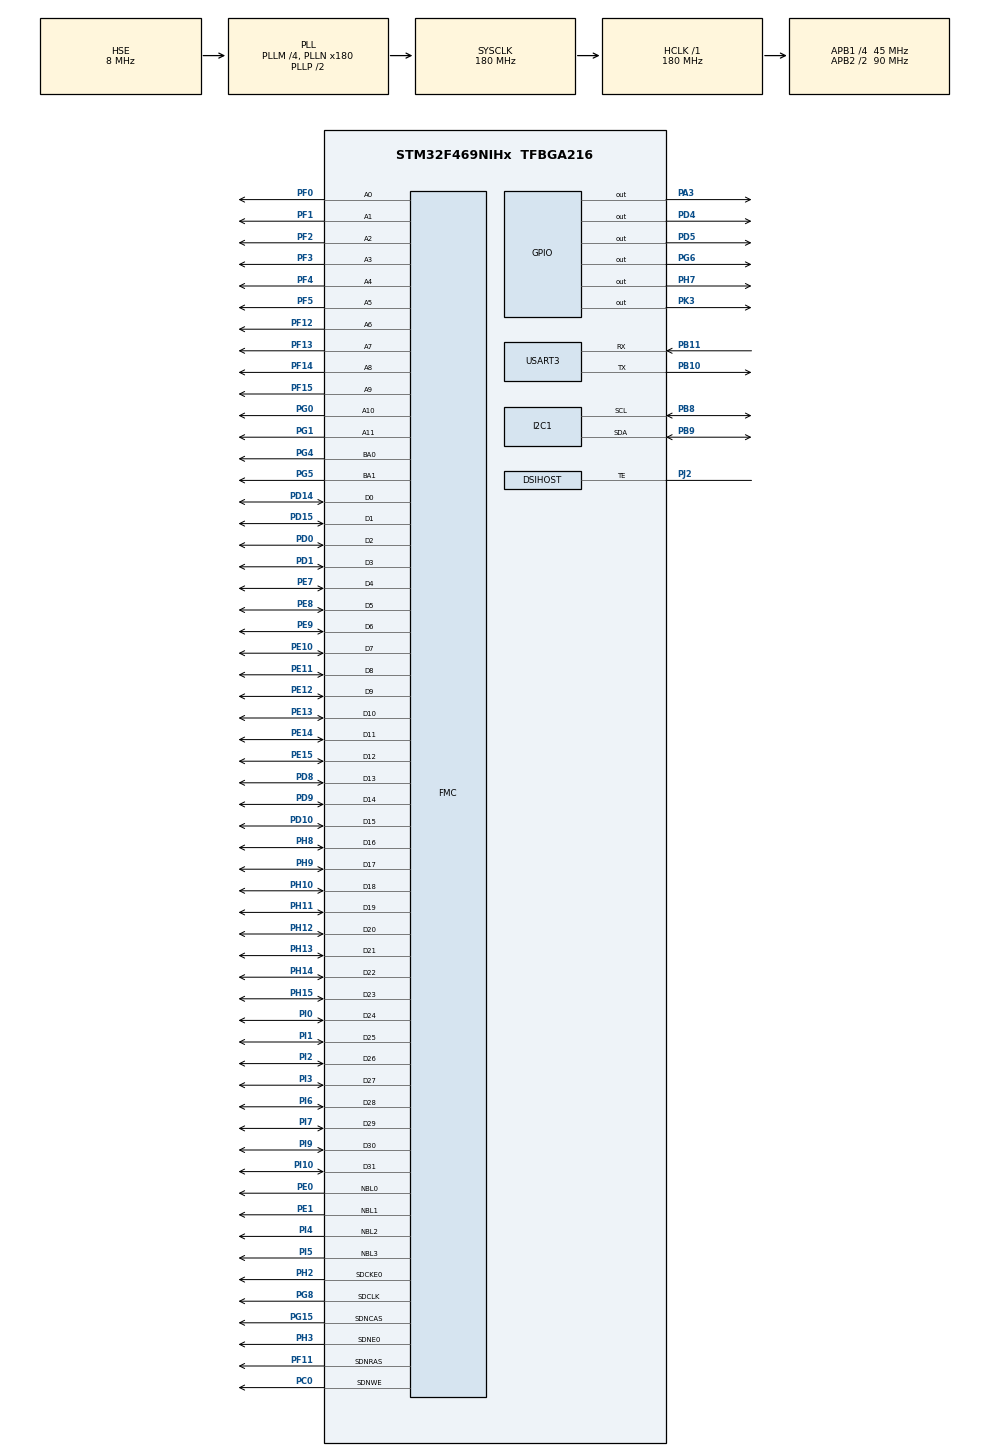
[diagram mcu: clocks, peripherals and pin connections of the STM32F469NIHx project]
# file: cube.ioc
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DSIHOST.CommandSize=200
DSIHOST.LPDcsLongWrite=DSI_LP_DLW_ENABLE
DSIHOST.LPDcsShortReadNoP=DSI_LP_DSR0P_ENABLE
DSIHOST.LPDcsShortWriteNoP=DSI_LP_DSW0P_ENABLE
DSIHOST.LPDcsShortWriteOneP=DSI_LP_DSW1P_ENABLE
DSIHOST.LPGenLongWrite=DSI_LP_GLW_ENABLE
DSIHOST.LPGenShortReadNoP=DSI_LP_GSR0P_ENABLE
DSIHOST.LPGenShortReadOneP=DSI_LP_GSR1P_ENABLE
DSIHOST.LPGenShortReadTwoP=DSI_LP_GSR2P_ENABLE
DSIHOST.LPGenShortWriteNoP=DSI_LP_GSW0P_ENABLE
DSIHOST.LPGenShortWriteOneP=DSI_LP_GSW1P_ENABLE
DSIHOST.LPGenShortWriteTwoP=DSI_LP_GSW2P_ENABLE
DSIHOST.LPMaxReadPacket=DSI_LP_MRDP_ENABLE
DSIHOST.NumberOfLanes=DSI_TWO_DATA_LANES
DSIHOST.StopWaitTime=10
DSIHOST.TEAcknowledgeRequest=DSI_TE_ACKNOWLEDGE_ENABLE
DSIHOST_CKN.Mode=DSIHost_Adapted_TE
DSIHOST_CKN.Signal=DSIHOST_CKN
DSIHOST_CKP.Mode=DSIHost_Adapted_TE
DSIHOST_CKP.Signal=DSIHOST_CKP
DSIHOST_D0N.Mode=DSIHost_Adapted_TE
DSIHOST_D0N.Signal=DSIHOST_D0N
DSIHOST_D0P.Mode=DSIHost_Adapted_TE
DSIHOST_D0P.Signal=DSIHOST_D0P
DSIHOST_D1N.Mode=DSIHost_Adapted_TE
DSIHOST_D1N.Signal=DSIHOST_D1N
DSIHOST_D1P.Mode=DSIHost_Adapted_TE
DSIHOST_D1P.Signal=DSIHOST_D1P
FMC.CASLatency1=FMC_SDRAM_CAS_LATENCY_3
FMC.ExitSelfRefreshDelay1=7
FMC.LoadToActiveDelay1=2
FMC.RCDDelay1=2
FMC.RPDelay1=2
FMC.ReadBurst1=FMC_SDRAM_RBURST_ENABLE
FMC.RowCycleDelay1=7
FMC.SDClockPeriod1=FMC_SDRAM_CLOCK_PERIOD_2
FMC.SelfRefreshTime1=4
FMC.WriteRecoveryTime1=3
GRAPHICS.BSP.number=1
GRAPHICS.Check_OTM8009A_PixelFormat-STemWin=1
GRAPHICS.DMA2D_Graphics-STemWin=1
GRAPHICS.EA_1_Apptype=Window
GRAPHICS.EA_1_custom_path=custom_on
GRAPHICS.EA_1_executable_name-STemWin=GUIBuilder.exe
GRAPHICS.GUI_NUM_LAYERS-STemWin=1
GRAPHICS.GUI_RGB_ORDERING=ARGB
GRAPHICS.LIN_Color_Conversion_Layer0=GUICC_M565
GRAPHICS.LIN_Frame_Buffer_Depth_Layer0-STemWin=16
GRAPHICS.Num_MultBuffers=2
GRAPHICS.OPTIM_OS_use-STemWin=4
GRAPHICS.USE_Embedded_Wizard-STemWin=0
GRAPHICS.USE_STTouchGFX-STemWin=0
GRAPHICS.UseGUIBuilder=Enabled
GRAPHICS.Use_SDRAM-STemWin=SDRAM1_BANK1
GRAPHICS.Xsize_PHYS=800
GRAPHICS.ZONE=4
GRAPHICS0.BSP.STBoard=false
GRAPHICS0.BSP.api=Unknown
GRAPHICS0.BSP.i2caddr=0
GRAPHICS0.BSP.instance=PH7
GRAPHICS0.BSP.ip=GPIO
GRAPHICS0.BSP.mode=Output
GRAPHICS0.BSP.name=LCD Reset Pin XRES
GRAPHICS0.BSP.solution=PH7
I2C1.I2C_Mode=I2C_Standard
LTDC.ActiveW=200
LTDC.Alpha_L0=255
LTDC.Alpha_L1=255
LTDC.BlendingFactor1_L0=LTDC_BLENDING_FACTOR1_PAxCA
LTDC.BlendingFactor1_L1=LTDC_BLENDING_FACTOR1_PAxCA
LTDC.BlendingFactor2_L0=LTDC_BLENDING_FACTOR2_PAxCA
LTDC.BlendingFactor2_L1=LTDC_BLENDING_FACTOR2_PAxCA
LTDC.FBStartAdress_L0=0xC0000000
LTDC.FBStartAdress_L1=0xC0120000
LTDC.HBP=1
LTDC.HFP=1
LTDC.HSync=1
LTDC.ImageHeight_L0=480
LTDC.ImageHeight_L1=480
LTDC.ImageWidth_L0=200
LTDC.ImageWidth_L1=200
LTDC.Layers=0
LTDC.PixelFormat_L0=LTDC_PIXEL_FORMAT_RGB565
LTDC.VBP=1
LTDC.VFP=1
LTDC.VSync=1
LTDC.WindowX1_L0=200
LTDC.WindowX1_L1=200
LTDC.WindowY1_L0=480
LTDC.WindowY1_L1=480
Mcu.Family=STM32F4
Mcu.Name=STM32F469NIHx
Mcu.Package=TFBGA216
NVIC.DMA2D_IRQn=true\:0\:0\:false\:false\:true\:true\:true
NVIC.DSI_IRQn=true\:0\:0\:false\:false\:true\:true\:true
NVIC.I2C1_ER_IRQn=true\:0\:0\:false\:false\:true\:true\:true
NVIC.I2C1_EV_IRQn=true\:0\:0\:false\:false\:true\:true\:true
NVIC.LTDC_IRQn=true\:0\:0\:false\:false\:true\:true\:true
NVIC.PriorityGroup=NVIC_PRIORITYGROUP_4
NVIC.USART3_IRQn=true\:0\:0\:false\:false\:true\:true\:true
PA13.Mode=Serial_Wire
PA13.Signal=SYS_JTMS-SWDIO
PA14.Mode=Serial_Wire
PA14.Signal=SYS_JTCK-SWCLK
PA3.Signal=GPIO_Output
PB10.Mode=Asynchronous
PB10.Signal=USART3_TX
PB11.Mode=Asynchronous
PB11.Signal=USART3_RX
PB8.Mode=I2C
PB8.Signal=I2C1_SCL
PB9.Mode=I2C
PB9.Signal=I2C1_SDA
PC0.Signal=FMC_SDNWE
PD0.Signal=FMC_D2_DA2
PD1.Signal=FMC_D3_DA3
PD10.Signal=FMC_D15_DA15
PD14.Signal=FMC_D0_DA0
PD15.Signal=FMC_D1_DA1
PD4.Signal=GPIO_Output
PD5.Signal=GPIO_Output
PD8.Signal=FMC_D13_DA13
PD9.Signal=FMC_D14_DA14
PE0.Signal=FMC_NBL0
PE1.Signal=FMC_NBL1
PE10.Signal=FMC_D7_DA7
PE11.Signal=FMC_D8_DA8
PE12.Signal=FMC_D9_DA9
PE13.Signal=FMC_D10_DA10
PE14.Signal=FMC_D11_DA11
PE15.Signal=FMC_D12_DA12
PE7.Signal=FMC_D4_DA4
PE8.Signal=FMC_D5_DA5
PE9.Signal=FMC_D6_DA6
PF0.Signal=FMC_A0
PF1.Signal=FMC_A1
PF11.Signal=FMC_SDNRAS
PF12.Signal=FMC_A6
PF13.Signal=FMC_A7
PF14.Signal=FMC_A8
PF15.Signal=FMC_A9
PF2.Signal=FMC_A2
PF3.Signal=FMC_A3
PF4.Signal=FMC_A4
PF5.Signal=FMC_A5
PG0.Signal=FMC_A10
PG1.Signal=FMC_A11
PG15.Signal=FMC_SDNCAS
PG4.Signal=FMC_A14_BA0
PG5.Signal=FMC_A15_BA1
PG6.Signal=GPIO_Output
PG8.Signal=FMC_SDCLK
PH0/OSC_IN.Mode=HSE-External-Oscillator
PH0/OSC_IN.Signal=RCC_OSC_IN
PH1/OSC_OUT.Mode=HSE-External-Oscillator
PH1/OSC_OUT.Signal=RCC_OSC_OUT
PH10.Signal=FMC_D18
PH11.Signal=FMC_D19
PH12.Signal=FMC_D20
PH13.Signal=FMC_D21
PH14.Signal=FMC_D22
PH15.Signal=FMC_D23
PH2.Mode=SdramChipSelect1_1
PH2.Signal=FMC_SDCKE0
PH3.Mode=SdramChipSelect1_1
PH3.Signal=FMC_SDNE0
PH7.Signal=GPIO_Output
PH8.Signal=FMC_D16
PH9.Signal=FMC_D17
PI0.Signal=FMC_D24
PI1.Signal=FMC_D25
PI10.Signal=FMC_D31
PI2.Signal=FMC_D26
PI3.Signal=FMC_D27
PI4.Signal=FMC_NBL2
PI5.Signal=FMC_NBL3
PI6.Signal=FMC_D28
PI7.Signal=FMC_D29
PI9.Signal=FMC_D30
PJ2.Mode=DSIHost_Adapted_TE
PJ2.Signal=DSIHOST_TE
PK3.Signal=GPIO_Output
ProjectManager.HeapSize=0x200
ProjectManager.StackSize=0x400
ProjectManager.TargetToolchain=TrueSTUDIO
RCC.AHBFreq_Value=180000000
RCC.APB1CLKDivider=RCC_HCLK_DIV4
RCC.APB1Freq_Value=45000000
RCC.APB1TimFreq_Value=90000000
RCC.APB2CLKDivider=RCC_HCLK_DIV2
RCC.APB2Freq_Value=90000000
RCC.APB2TimFreq_Value=180000000
RCC.CortexFreq_Value=180000000
RCC.HCLKFreq_Value=180000000
RCC.HSE_VALUE=8000000
RCC.PLLDSIIDF=DSI_PLL_IN_DIV2
RCC.PLLDSINDIV=125
RCC.PLLM=4
RCC.PLLN=180
RCC.PLLSAIN=72
RCC.PLLSourceVirtual=RCC_PLLSOURCE_HSE
RCC.SYSCLKFreq_VALUE=180000000
RCC.SYSCLKSource=RCC_SYSCLKSOURCE_PLLCLK
RCC.USBFreq_Value=90000000
RCC.VCOOutputFreq_Value=360000000
SH.FMC_A0.0=FMC_A0,12b-sda1
SH.FMC_A1.0=FMC_A1,12b-sda1
SH.FMC_A10.0=FMC_A10,12b-sda1
SH.FMC_A11.0=FMC_A11,12b-sda1
SH.FMC_A14_BA0.0=FMC_BA0,FourSdramBanks1
SH.FMC_A15_BA1.0=FMC_BA1,FourSdramBanks1
SH.FMC_A2.0=FMC_A2,12b-sda1
SH.FMC_A3.0=FMC_A3,12b-sda1
SH.FMC_A4.0=FMC_A4,12b-sda1
SH.FMC_A5.0=FMC_A5,12b-sda1
SH.FMC_A6.0=FMC_A6,12b-sda1
SH.FMC_A7.0=FMC_A7,12b-sda1
SH.FMC_A8.0=FMC_A8,12b-sda1
SH.FMC_A9.0=FMC_A9,12b-sda1
SH.FMC_D0_DA0.0=FMC_D0,sd-32b-d1
SH.FMC_D10_DA10.0=FMC_D10,sd-32b-d1
SH.FMC_D11_DA11.0=FMC_D11,sd-32b-d1
SH.FMC_D12_DA12.0=FMC_D12,sd-32b-d1
SH.FMC_D13_DA13.0=FMC_D13,sd-32b-d1
SH.FMC_D14_DA14.0=FMC_D14,sd-32b-d1
SH.FMC_D15_DA15.0=FMC_D15,sd-32b-d1
SH.FMC_D16.0=FMC_D16,sd-32b-d1
SH.FMC_D17.0=FMC_D17,sd-32b-d1
SH.FMC_D18.0=FMC_D18,sd-32b-d1
SH.FMC_D19.0=FMC_D19,sd-32b-d1
SH.FMC_D1_DA1.0=FMC_D1,sd-32b-d1
SH.FMC_D20.0=FMC_D20,sd-32b-d1
SH.FMC_D21.0=FMC_D21,sd-32b-d1
SH.FMC_D22.0=FMC_D22,sd-32b-d1
SH.FMC_D23.0=FMC_D23,sd-32b-d1
SH.FMC_D24.0=FMC_D24,sd-32b-d1
SH.FMC_D25.0=FMC_D25,sd-32b-d1
SH.FMC_D26.0=FMC_D26,sd-32b-d1
SH.FMC_D27.0=FMC_D27,sd-32b-d1
SH.FMC_D28.0=FMC_D28,sd-32b-d1
SH.FMC_D29.0=FMC_D29,sd-32b-d1
SH.FMC_D2_DA2.0=FMC_D2,sd-32b-d1
SH.FMC_D30.0=FMC_D30,sd-32b-d1
SH.FMC_D31.0=FMC_D31,sd-32b-d1
SH.FMC_D3_DA3.0=FMC_D3,sd-32b-d1
SH.FMC_D4_DA4.0=FMC_D4,sd-32b-d1
SH.FMC_D5_DA5.0=FMC_D5,sd-32b-d1
SH.FMC_D6_DA6.0=FMC_D6,sd-32b-d1
SH.FMC_D7_DA7.0=FMC_D7,sd-32b-d1
SH.FMC_D8_DA8.0=FMC_D8,sd-32b-d1
SH.FMC_D9_DA9.0=FMC_D9,sd-32b-d1
SH.FMC_NBL0.0=FMC_NBL0,Sd4ByteEnable1
SH.FMC_NBL1.0=FMC_NBL1,Sd4ByteEnable1
SH.FMC_NBL2.0=FMC_NBL2,Sd4ByteEnable1
SH.FMC_NBL3.0=FMC_NBL3,Sd4ByteEnable1
SH.FMC_SDCLK.0=FMC_SDCLK,12b-sda1
SH.FMC_SDNCAS.0=FMC_SDNCAS,12b-sda1
SH.FMC_SDNRAS.0=FMC_SDNRAS,12b-sda1
SH.FMC_SDNWE.0=FMC_SDNWE,12b-sda1
USART3.VirtualMode=VM_ASYNC
VP_CRC_VS_CRC.Mode=CRC_Activate
VP_DMA2D_VS_DMA2D.Mode=DMA2D_Activate
VP_GRAPHICS_VS-DisplayInterface-DSI-LTDC.Mode=Display Serial Interface using LTDC-DSIHOST
VP_GRAPHICS_VS-STemWin.Mode=STemWin
VP_LTDC_DSIMode.Mode=RGB888
VP_TIM2_VS_ClockSourceINT.Mode=Internal
board=custom

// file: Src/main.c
/* USER CODE BEGIN Header */
/**
  ******************************************************************************
  * @file           : main.c
  * @brief          : Main program body
  ******************************************************************************
  * @attention
  *
  * <h2><center>&copy; Copyright (c) 2019 STMicroelectronics.
  * All rights reserved.</center></h2>
  *
  * This software component is licensed by ST under BSD 3-Clause license,
  * the "License"; You may not use this file except in compliance with the
  * License. You may obtain a copy of the License at:
  *                        opensource.org/licenses/BSD-3-Clause
  *
  ******************************************************************************
  */
/* USER CODE END Header */

#include "main.h"
#include "crc.h"
#include "i2c.h"
#include "tim.h"
#include "usart.h"
#include "gpio.h"

void SystemClock_Config(void);
extern void GRAPHICS_HW_Init(void);
extern void GRAPHICS_Init(void);
extern void GRAPHICS_MainTask(void);

/* USER CODE BEGIN 0 */
static int main(void);

void cubeInit(void)
{
  main();
}
/* USER CODE END 0 */

int main(void)
{

  /* MCU Configuration--------------------------------------------------------*/

  /* Reset of all peripherals, Initializes the Flash interface and the Systick. */
  HAL_Init();

  /* Configure the system clock */
  SystemClock_Config();

  /* Initialize all configured peripherals */
  MX_GPIO_Init();
  MX_TIM2_Init();
  MX_USART3_UART_Init();
  MX_CRC_Init();
  MX_I2C1_Init();
  /* USER CODE BEGIN 2 */
  return 0;

  /* USER CODE END 2 */

/* Initialise the graphical hardware */
  GRAPHICS_HW_Init();

  /* Initialise the graphical stack engine */
  GRAPHICS_Init();

  /* Graphic application */
  GRAPHICS_MainTask();

  /* Infinite loop */
  for(;;);
}

void SystemClock_Config(void)
{
  RCC_OscInitTypeDef RCC_OscInitStruct = {0};
  RCC_ClkInitTypeDef RCC_ClkInitStruct = {0};
  RCC_PeriphCLKInitTypeDef PeriphClkInitStruct = {0};

  /** Configure the main internal regulator output voltage
  */
  __HAL_RCC_PWR_CLK_ENABLE();
  __HAL_PWR_VOLTAGESCALING_CONFIG(PWR_REGULATOR_VOLTAGE_SCALE1);
  /** Initializes the CPU, AHB and APB busses clocks
  */
  RCC_OscInitStruct.OscillatorType = RCC_OSCILLATORTYPE_HSE;
  RCC_OscInitStruct.HSEState = RCC_HSE_ON;
  RCC_OscInitStruct.PLL.PLLState = RCC_PLL_ON;
  RCC_OscInitStruct.PLL.PLLSource = RCC_PLLSOURCE_HSE;
  RCC_OscInitStruct.PLL.PLLM = 4;
  RCC_OscInitStruct.PLL.PLLN = 180;
  RCC_OscInitStruct.PLL.PLLP = RCC_PLLP_DIV2;
  RCC_OscInitStruct.PLL.PLLQ = 4;
  RCC_OscInitStruct.PLL.PLLR = 2;
  if (HAL_RCC_OscConfig(&RCC_OscInitStruct) != HAL_OK)
  {
    Error_Handler();
  }
  /** Activate the Over-Drive mode
  */
  if (HAL_PWREx_EnableOverDrive() != HAL_OK)
  {
    Error_Handler();
  }
  /** Initializes the CPU, AHB and APB busses clocks
  */
  RCC_ClkInitStruct.ClockType = RCC_CLOCKTYPE_HCLK|RCC_CLOCKTYPE_SYSCLK
                              |RCC_CLOCKTYPE_PCLK1|RCC_CLOCKTYPE_PCLK2;
  RCC_ClkInitStruct.SYSCLKSource = RCC_SYSCLKSOURCE_PLLCLK;
  RCC_ClkInitStruct.AHBCLKDivider = RCC_SYSCLK_DIV1;
  RCC_ClkInitStruct.APB1CLKDivider = RCC_HCLK_DIV4;
  RCC_ClkInitStruct.APB2CLKDivider = RCC_HCLK_DIV2;

  if (HAL_RCC_ClockConfig(&RCC_ClkInitStruct, FLASH_LATENCY_5) != HAL_OK)
  {
    Error_Handler();
  }
  PeriphClkInitStruct.PeriphClockSelection = RCC_PERIPHCLK_LTDC;
  PeriphClkInitStruct.PLLSAI.PLLSAIN = 72;
  PeriphClkInitStruct.PLLSAI.PLLSAIR = 2;
  PeriphClkInitStruct.PLLSAIDivR = RCC_PLLSAIDIVR_2;
  if (HAL_RCCEx_PeriphCLKConfig(&PeriphClkInitStruct) != HAL_OK)
  {
    Error_Handler();
  }
}

void Error_Handler(void)
{
}

/************************ (C) COPYRIGHT STMicroelectronics *****END OF FILE****/
